# STM32WLE5xx register map
File version: 1.0
Registers are 32-bit, read-write, reset 0x0 unless marked. A register's access mark holds for its fields unless they carry their own. Offsets are from the block's base; [hi:lo] are bit positions; {n}, {i} and the like mark numbered series.

## SYSCFG — System configuration controller
Base 0x40010000
0x00 MEMRMP — SYSCFG memory remap register
  [2:0] MEM_MODE — SYSCFG_Memory Remap Config
    0=FLASH (Main Flash memory mapped at 0x00000000); 1=SYSTEMFLASH (System Flash memory mapped at 0x00000000); 3=SRAM (SRAM1 mapped at 0x00000000)
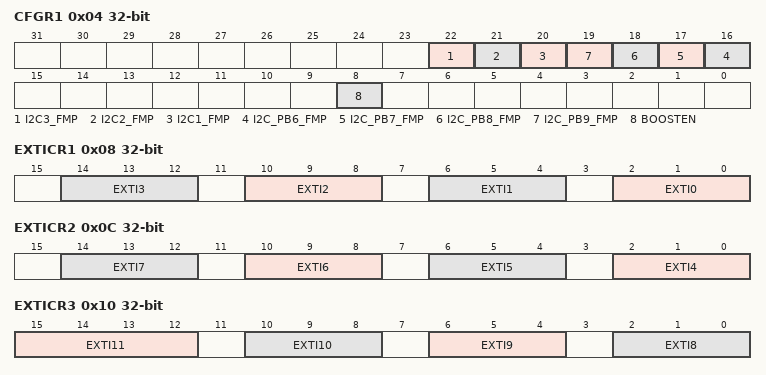
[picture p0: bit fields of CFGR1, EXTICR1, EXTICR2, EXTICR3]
0x04 CFGR1 — SYSCFG configuration register 1
  [22] I2C3_FMP — I2C3 Fast-mode Plus (Fm+) driving capability activation
  [21] I2C2_FMP — I2C2 Fast-mode Plus (Fm+) driving capability activation
  [20] I2C1_FMP — I2C1 Fast-mode Plus (Fm+) driving capability activation
  [n+10] I2C_PB{n}_FMP (n=6..9) — Fast-mode Plus (Fm+) driving capability activation on PB{n}
  [8] BOOSTEN — I/O analog switch voltage booster enable
0x08 EXTICR1 — SYSCFG external interrupt configuration registers
  [4n+2:4n] EXTI{n} (n=0..3) — External Interrupt Line {n} configuration
0x0C EXTICR2 — SYSCFG external interrupt configuration registers
  [4n-14:4n-16] EXTI{n} (n=4..7) — External Interrupt Line {n} configuration
0x10 EXTICR3 — SYSCFG external interrupt configuration registers
  [15:12] EXTI11 — External Interrupt Line 11 configuration
  [10:8] EXTI10 — External Interrupt Line 10 configuration
  [6:4] EXTI9 — External Interrupt Line 9 configuration
  [2:0] EXTI8 — External Interrupt Line 8 configuration
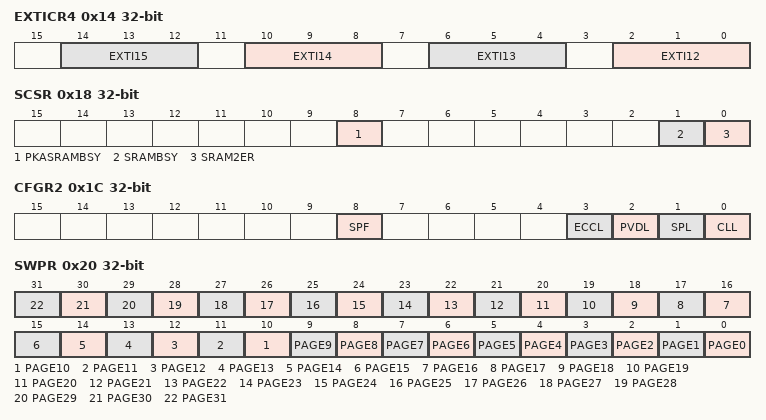
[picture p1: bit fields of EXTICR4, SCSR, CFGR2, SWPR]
0x14 EXTICR4 — SYSCFG external interrupt configuration registers
  [4n-46:4n-48] EXTI{n} (n=12..15) — External Interrupt Line {n} configuration
0x18 SCSR — SYSCFG SRAM2 control and status register
  [8] PKASRAMBSY — PKA SRAM busy by erase operation
  [1] SRAMBSY — SRAM2 and SRAM1 busy by erase operation
  [0] SRAM2ER — SRAM2 Erase
0x1C CFGR2 — SYSCFG configuration register 2
  [8] SPF — SRAM2 Parity Lock
  [3] ECCL — ECC Lock
  [2] PVDL — PVD Lock
  [1] SPL — SRAM2 Parity Lock
  [0] CLL — Cortex M4 LOCKUP (hardfault) output enable
0x20 SWPR — SYSCFG SRAM2 write protection register part
  [n] PAGE{n} (n=0..31) — SRAM2 Write protection page {n} ({0x20008000+0x400*n} - {0x200083FF+0x400*n})
0x24 SKR — SYSCFG SRAM2 key register
  [7:0] KEY — SRAM2 write protection key for software erase
0x208 RFDCR — SYSCFG CPU2 radio debug control register
  [0] RFTBSEL — Radio debug test bus selection
    1=ANALOG_TEST_BUS (Analog test bus selected on RF_ADTB[3:0]); 0=DIGITAL_TEST_BUS (Digital test bus selected on RF_ADTB[3:0])

## VREFBUF
Base 0x40010030
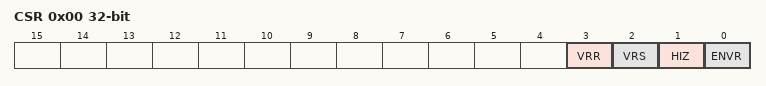
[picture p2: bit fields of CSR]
0x00 CSR — VREFBUF control and status register
  [3] VRR — Voltage reference scale
  [2] VRS — Voltage reference buffer ready
    0=SCALE0 (Voltage reference scale 0 (VREF_OUT1)); 1=SCALE1 (Voltage reference scale 1 (VREF_OUT2))
  [1] HIZ — High impedance mode
  [0] ENVR — Voltage reference buffer enable
0x04 CCR — VREFBUF calibration and control register
  [5:0] TRIM — TRIM[5:0] bits (Trimming code)

## COMP1 — Comparator
Base 0x40010200
Same registers: COMP2 0x40010204 (alternate view of COMP12_COMMON)
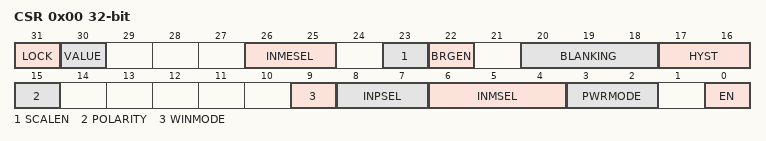
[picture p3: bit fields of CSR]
0x00 CSR — COMP control and status register
  [31] LOCK — Comparator lock
  [30] VALUE — Comparator output level
  [26:25] INMESEL — Comparator input minus extended selection
  [23] SCALEN — Comparator scaler bridge enable
  [22] BRGEN — Comparator voltage scaler enable
  [20:18] BLANKING — Comparator blanking source
    0=NONE (Comparator output without blanking); 1=TIM1_OC5 (Comparator output blanking source TIM1 OC5 (common to all COMP instances: COMP1, COMP2)); 2=TIM2_OC3 (Comparator output blanking source TIM2 OC3 (common to all COMP instances: COMP1, COMP2))
  [17:16] HYST — Comparator hysteresis
    0=NONE (No hysteresis); 1=LOW (Hysteresis level low); 2=MEDIUM (Hysteresis level medium); 3=HIGH (Hysteresis level high)
  [15] POLARITY — Comparator output polarity
    0=NONINVERTED (COMP output polarity is not inverted: comparator output is high when the plus (non-inverting) input is at a higher voltage than the minus (inverting) input); 1=INVERTED (COMP output polarity is inverted: comparator output is low when the plus (non-inverting) input is at a lower voltage than the minus (inverting) input)
  [9] WINMODE — Pair of comparators window mode. Bit intended to be used with COMP common instance (COMP_Common_TypeDef)
    0=DISABLE (Window mode disable: Comparators 1 and 2 are independent); 1=COMP1_INPUT_PLUS_COMMON (Window mode enable: Comparators instances pair COMP1 and COMP2 have their input plus connected together. The common input is COMP1 input plus (COMP2 input plus is no more accessible).)
  [8:7] INPSEL — Comparator input plus selection
    0=IO1 (Comparator input plus connected to IO1 (pin PB4 for COMP1, pin PB4 for COMP2)); 1=IO2 (Comparator input plus connected to IO2 (pin PB2 for COMP1, pin PB1 for COMP2)); 2=IO3 (Comparator input plus connected to IO2 (not applicable for COMP1, pin PA15 for COMP2))
  [6:4] INMSEL — Comparator input minus selection
  [3:2] PWRMODE — Comparator power mode
    0=HIGHSPEED (COMP power mode to high speed); 1=MEDIUMSPEED (COMP power mode to medium speed); 3=ULTRALOWPOWER (COMP power mode to ultra-low power)
  [0] EN — Comparator enable
